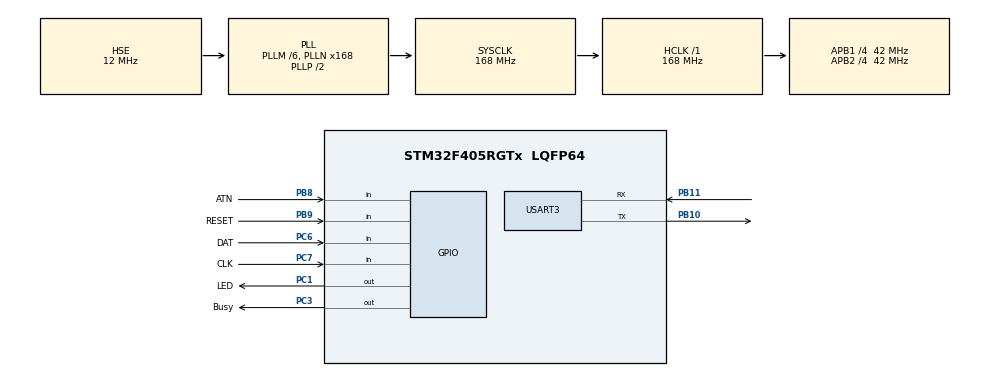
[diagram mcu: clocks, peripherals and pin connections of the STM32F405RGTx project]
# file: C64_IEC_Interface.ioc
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Mcu.Family=STM32F4
Mcu.Name=STM32F405RGTx
Mcu.Package=LQFP64
NVIC.PriorityGroup=NVIC_PRIORITYGROUP_4
NVIC.USART3_IRQn=true\:0\:0\:false\:false\:true\:true\:true\:true
PA13.Mode=Serial_Wire
PA13.Signal=SYS_JTMS-SWDIO
PA14.Mode=Serial_Wire
PA14.Signal=SYS_JTCK-SWCLK
PB10.Mode=Asynchronous
PB10.Signal=USART3_TX
PB11.Mode=Asynchronous
PB11.Signal=USART3_RX
PB8.GPIO_Label=ATN
PB8.Signal=GPIO_Input
PB9.GPIO_Label=RESET
PB9.Signal=GPIO_Input
PC1.GPIO_Label=LED
PC1.Signal=GPIO_Output
PC14-OSC32_IN.Mode=LSE-External-Oscillator
PC14-OSC32_IN.Signal=RCC_OSC32_IN
PC15-OSC32_OUT.Mode=LSE-External-Oscillator
PC15-OSC32_OUT.Signal=RCC_OSC32_OUT
PC3.GPIO_Label=Busy
PC3.Signal=GPIO_Output
PC6.GPIO_Label=DAT
PC6.Signal=GPIO_Input
PC7.GPIO_Label=CLK
PC7.Signal=GPIO_Input
PH0-OSC_IN.Mode=HSE-External-Oscillator
PH0-OSC_IN.Signal=RCC_OSC_IN
PH1-OSC_OUT.Mode=HSE-External-Oscillator
PH1-OSC_OUT.Signal=RCC_OSC_OUT
ProjectManager.HeapSize=0x200
ProjectManager.StackSize=0x400
ProjectManager.TargetToolchain=STM32CubeIDE
RCC.48MHZClocksFreq_Value=84000000
RCC.AHBFreq_Value=168000000
RCC.APB1CLKDivider=RCC_HCLK_DIV4
RCC.APB1Freq_Value=42000000
RCC.APB1TimFreq_Value=84000000
RCC.APB2CLKDivider=RCC_HCLK_DIV4
RCC.APB2Freq_Value=42000000
RCC.APB2TimFreq_Value=84000000
RCC.CortexFreq_Value=168000000
RCC.HCLKFreq_Value=168000000
RCC.HSE_VALUE=12000000
RCC.HSI_VALUE=16000000
RCC.PLLM=6
RCC.PLLN=168
RCC.PLLSourceVirtual=RCC_PLLSOURCE_HSE
RCC.SYSCLKFreq_VALUE=168000000
RCC.SYSCLKSource=RCC_SYSCLKSOURCE_PLLCLK
RCC.VCOOutputFreq_Value=336000000
TIM7.Prescaler=84-1
USART3.VirtualMode=VM_ASYNC
VP_TIM7_VS_ClockSourceINT.Mode=Enable_Timer
board=custom

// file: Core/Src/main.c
/* USER CODE BEGIN Header */
/**
  ******************************************************************************
  * @file           : main.c
  * @brief          : Main program body
  ******************************************************************************
  * @attention
  *
  * Copyright (c) 2025 STMicroelectronics.
  * All rights reserved.
  *
  * This software is licensed under terms that can be found in the LICENSE file
  * in the root directory of this software component.
  * If no LICENSE file comes with this software, it is provided AS-IS.
  *
  ******************************************************************************
  */
/* USER CODE END Header */
#include "main.h"

/* USER CODE BEGIN Includes */
#include "program.h"
/* USER CODE END Includes */

TIM_HandleTypeDef htim7;

UART_HandleTypeDef huart3;

void SystemClock_Config(void);
static void MX_GPIO_Init(void);
static void MX_TIM7_Init(void);
static void MX_USART3_UART_Init(void);

int main(void)
{

  /* MCU Configuration--------------------------------------------------------*/

  /* Reset of all peripherals, Initializes the Flash interface and the Systick. */
  HAL_Init();

  /* Configure the system clock */
  SystemClock_Config();

  /* Initialize all configured peripherals */
  MX_GPIO_Init();
  MX_TIM7_Init();
  MX_USART3_UART_Init();

  /* Infinite loop */
  /* USER CODE BEGIN WHILE */

  run();
  while (1)
  {
    /* USER CODE END WHILE */

  }
}

void SystemClock_Config(void)
{
  RCC_OscInitTypeDef RCC_OscInitStruct = {0};
  RCC_ClkInitTypeDef RCC_ClkInitStruct = {0};

  /** Configure the main internal regulator output voltage
  */
  __HAL_RCC_PWR_CLK_ENABLE();
  __HAL_PWR_VOLTAGESCALING_CONFIG(PWR_REGULATOR_VOLTAGE_SCALE1);

  /** Initializes the RCC Oscillators according to the specified parameters
  * in the RCC_OscInitTypeDef structure.
  */
  RCC_OscInitStruct.OscillatorType = RCC_OSCILLATORTYPE_HSE;
  RCC_OscInitStruct.HSEState = RCC_HSE_ON;
  RCC_OscInitStruct.PLL.PLLState = RCC_PLL_ON;
  RCC_OscInitStruct.PLL.PLLSource = RCC_PLLSOURCE_HSE;
  RCC_OscInitStruct.PLL.PLLM = 6;
  RCC_OscInitStruct.PLL.PLLN = 168;
  RCC_OscInitStruct.PLL.PLLP = RCC_PLLP_DIV2;
  RCC_OscInitStruct.PLL.PLLQ = 4;
  if (HAL_RCC_OscConfig(&RCC_OscInitStruct) != HAL_OK)
  {
    Error_Handler();
  }

  /** Initializes the CPU, AHB and APB buses clocks
  */
  RCC_ClkInitStruct.ClockType = RCC_CLOCKTYPE_HCLK|RCC_CLOCKTYPE_SYSCLK
                              |RCC_CLOCKTYPE_PCLK1|RCC_CLOCKTYPE_PCLK2;
  RCC_ClkInitStruct.SYSCLKSource = RCC_SYSCLKSOURCE_PLLCLK;
  RCC_ClkInitStruct.AHBCLKDivider = RCC_SYSCLK_DIV1;
  RCC_ClkInitStruct.APB1CLKDivider = RCC_HCLK_DIV4;
  RCC_ClkInitStruct.APB2CLKDivider = RCC_HCLK_DIV4;

  if (HAL_RCC_ClockConfig(&RCC_ClkInitStruct, FLASH_LATENCY_5) != HAL_OK)
  {
    Error_Handler();
  }
}

static void MX_TIM7_Init(void)
{

  TIM_MasterConfigTypeDef sMasterConfig = {0};

  htim7.Instance = TIM7;
  htim7.Init.Prescaler = 84-1;
  htim7.Init.CounterMode = TIM_COUNTERMODE_UP;
  htim7.Init.Period = 65535;
  htim7.Init.AutoReloadPreload = TIM_AUTORELOAD_PRELOAD_DISABLE;
  if (HAL_TIM_Base_Init(&htim7) != HAL_OK)
  {
    Error_Handler();
  }
  sMasterConfig.MasterOutputTrigger = TIM_TRGO_RESET;
  sMasterConfig.MasterSlaveMode = TIM_MASTERSLAVEMODE_DISABLE;
  if (HAL_TIMEx_MasterConfigSynchronization(&htim7, &sMasterConfig) != HAL_OK)
  {
    Error_Handler();
  }
  /* USER CODE BEGIN TIM7_Init 2 */
  __HAL_TIM_ENABLE(&htim7);
  /* USER CODE END TIM7_Init 2 */

}

static void MX_USART3_UART_Init(void)
{

  huart3.Instance = USART3;
  huart3.Init.BaudRate = 115200;
  huart3.Init.WordLength = UART_WORDLENGTH_8B;
  huart3.Init.StopBits = UART_STOPBITS_1;
  huart3.Init.Parity = UART_PARITY_NONE;
  huart3.Init.Mode = UART_MODE_TX_RX;
  huart3.Init.HwFlowCtl = UART_HWCONTROL_NONE;
  huart3.Init.OverSampling = UART_OVERSAMPLING_16;
  if (HAL_UART_Init(&huart3) != HAL_OK)
  {
    Error_Handler();
  }
  /* USER CODE BEGIN USART3_Init 2 */
  if (huart3.Init.Parity != UART_PARITY_NONE)
  {
	  __HAL_UART_ENABLE_IT(&huart3, UART_IT_PE); // Enable the UART Parity Error Interrupt
  }
  __HAL_UART_ENABLE_IT(&huart3, UART_IT_ERR); // Enable the UART Error Interrupt: (Frame error, noise error, overrun error)
  __HAL_UART_ENABLE_IT(&huart3, UART_IT_RXNE); // Enable the UART Data Register not empty Interrupt
  /* USER CODE END USART3_Init 2 */

}

static void MX_GPIO_Init(void)
{
  GPIO_InitTypeDef GPIO_InitStruct = {0};

  /* GPIO Ports Clock Enable */
  __HAL_RCC_GPIOC_CLK_ENABLE();
  __HAL_RCC_GPIOH_CLK_ENABLE();
  __HAL_RCC_GPIOB_CLK_ENABLE();
  __HAL_RCC_GPIOA_CLK_ENABLE();

  /*Configure GPIO pin Output Level */
  HAL_GPIO_WritePin(GPIOC, LED_Pin|Busy_Pin, GPIO_PIN_RESET);

  /*Configure GPIO pins : LED_Pin Busy_Pin */
  GPIO_InitStruct.Pin = LED_Pin|Busy_Pin;
  GPIO_InitStruct.Mode = GPIO_MODE_OUTPUT_PP;
  GPIO_InitStruct.Pull = GPIO_NOPULL;
  GPIO_InitStruct.Speed = GPIO_SPEED_FREQ_LOW;
  HAL_GPIO_Init(GPIOC, &GPIO_InitStruct);

  /*Configure GPIO pins : DAT_Pin CLK_Pin */
  GPIO_InitStruct.Pin = DAT_Pin|CLK_Pin;
  GPIO_InitStruct.Mode = GPIO_MODE_INPUT;
  GPIO_InitStruct.Pull = GPIO_NOPULL;
  HAL_GPIO_Init(GPIOC, &GPIO_InitStruct);

  /*Configure GPIO pins : ATN_Pin RESET_Pin */
  GPIO_InitStruct.Pin = ATN_Pin|RESET_Pin;
  GPIO_InitStruct.Mode = GPIO_MODE_INPUT;
  GPIO_InitStruct.Pull = GPIO_NOPULL;
  HAL_GPIO_Init(GPIOB, &GPIO_InitStruct);

}

void Error_Handler(void)
{
  __disable_irq();
  while (1)
  {
  }
}
